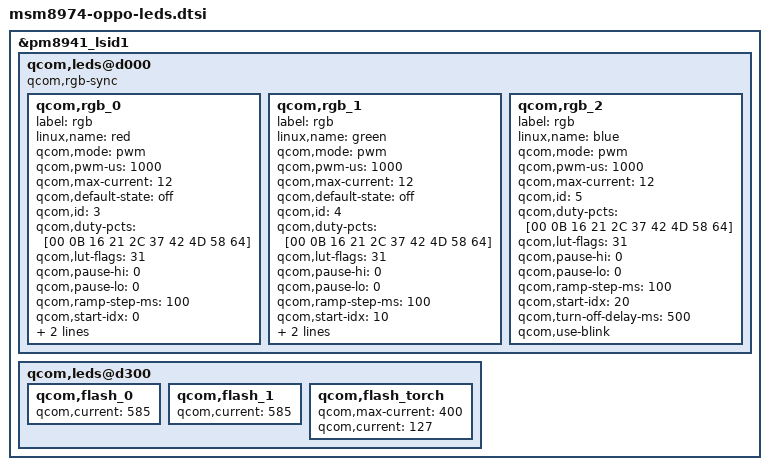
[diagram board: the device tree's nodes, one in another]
/*
 * Copyright (c) 2012-2013, The Linux Foundation. All rights reserved.
 *
 * This program is free software; you can redistribute it and/or modify
 * it under the terms of the GNU General Public License version 2 and
 * only version 2 as published by the Free Software Foundation.
 *
 * This program is distributed in the hope that it will be useful,
 * but WITHOUT ANY WARRANTY; without even the implied warranty of
 * MERCHANTABILITY or FITNESS FOR A PARTICULAR PURPOSE.  See the
 * GNU General Public License for more details.
 */

#include "../../qcom/msm8974-leds.dtsi"

&pm8941_lsid1 {
	qcom,leds@d000 {
		qcom,rgb-sync;

		status = "okay";
		qcom,rgb_0 {
			label = "rgb";
			linux,name = "red";
			qcom,mode = "pwm";
			qcom,pwm-us = <1000>;
			qcom,max-current = <12>;
			qcom,default-state = "off";
			qcom,id = <3>;
			qcom,duty-pcts = [00 0B 16 21 2C 37 42 4D 58 64];
			qcom,lut-flags = <31>; /* loop, ramp up, reverse, pause hi, pause lo */
			qcom,pause-hi = <0>;
			qcom,pause-lo = <0>;
			qcom,ramp-step-ms = <100>;
			qcom,start-idx = <0>;
			qcom,turn-off-delay-ms = <500>;
			qcom,use-blink;
			/delete-property/ linux,default-trigger;
		};

		qcom,rgb_1 {
			label = "rgb";
			linux,name = "green";
			qcom,mode = "pwm";
			qcom,pwm-us = <1000>;
			qcom,max-current = <12>;
			qcom,default-state = "off";
			qcom,id = <4>;
			qcom,duty-pcts = [00 0B 16 21 2C 37 42 4D 58 64];
			qcom,lut-flags = <31>; /* loop, ramp up, reverse, pause hi, pause lo */
			qcom,pause-hi = <0>;
			qcom,pause-lo = <0>;
			qcom,ramp-step-ms = <100>;
			qcom,start-idx = <10>;
			qcom,turn-off-delay-ms = <500>;
			qcom,use-blink;
			/delete-property/ linux,default-trigger;
		};

		qcom,rgb_2 {
			label = "rgb";
			linux,name = "blue";
			qcom,mode = "pwm";
			qcom,pwm-us = <1000>;
			qcom,max-current = <12>;
			qcom,id = <5>;
			qcom,duty-pcts = [00 0B 16 21 2C 37 42 4D 58 64];
			qcom,lut-flags = <31>; /* loop, ramp up, reverse, pause hi, pause lo */
			qcom,pause-hi = <0>;
			qcom,pause-lo = <0>;
			qcom,ramp-step-ms = <100>;
			qcom,start-idx = <20>;
			qcom,turn-off-delay-ms = <500>;
			qcom,use-blink;
			status = "ok";
		};
	};

	qcom,leds@d300 {
		qcom,flash_0 {
			qcom,current = <585>;
		};

		qcom,flash_1 {
			qcom,current = <585>;
		};

		qcom,flash_torch {
			qcom,max-current = <400>;
			qcom,current = <127>;
		};
	};
};

